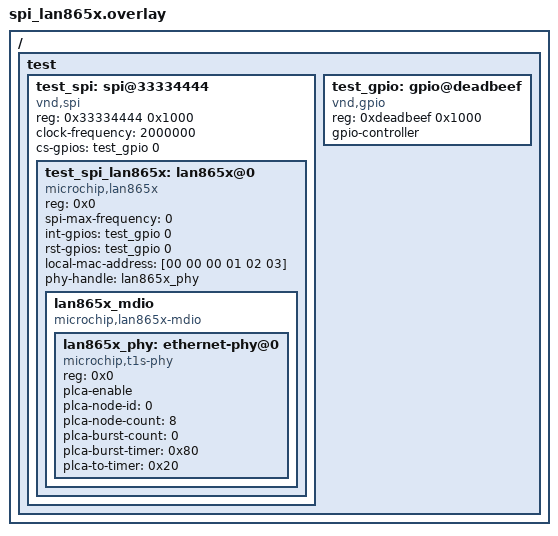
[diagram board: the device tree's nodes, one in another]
/*
 * Copyright (c) 2026 Mario Paja
 *
 * SPDX-License-Identifier: Apache-2.0
 *
 * LAN865x as the only driver using oa_tc6.c, so that it has to enable
 * everything it needs on its own.
 */

/ {
	test {
		#address-cells = <1>;
		#size-cells = <1>;

		test_spi: spi@33334444 {
			compatible = "vnd,spi";
			reg = <0x33334444 0x1000>;
			#address-cells = <1>;
			#size-cells = <0>;
			clock-frequency = <2000000>;
			cs-gpios = <&test_gpio 0 0>;
			status = "okay";

			test_spi_lan865x: lan865x@0 {
				compatible = "microchip,lan865x";
				reg = <0x0>;
				spi-max-frequency = <0>;
				int-gpios = <&test_gpio 0 0>;
				rst-gpios = <&test_gpio 0 0>;
				local-mac-address = [00 00 00 01 02 03];
				phy-handle = <&lan865x_phy>;

				lan865x_mdio: lan865x_mdio {
					compatible = "microchip,lan865x-mdio";
					#address-cells = <1>;
					#size-cells = <0>;
					status = "okay";

					lan865x_phy: ethernet-phy@0 {
						compatible = "microchip,t1s-phy";
						reg = <0x0>;
						plca-enable;
						plca-node-id = <0>;
						plca-node-count = <8>;
						plca-burst-count = <0>;
						plca-burst-timer = <0x80>;
						plca-to-timer = <0x20>;
						status = "okay";
					};
				};
			};
		};

		test_gpio: gpio@deadbeef {
			compatible = "vnd,gpio";
			reg = <0xdeadbeef 0x1000>;
			gpio-controller;
			#gpio-cells = <0x2>;
			status = "okay";
		};
	};
};
